VERSION ""

NS_ :

BS_:

BU_: JETSON VCU ACU RES DYN_F DYN_R FSG_DATA_LOGGER AK10_9 Acquisition_Board1 Acquisition_Board2 Acquisition_Board3 Acquisition_Board4 Acquisition_Board7

BO_ 3221225472 VECTOR__INDEPENDENT_SIG_MSG: 0 Vector__XXX
 SG_ WHEEL_SPD : 0|16@1- (0.1,0) [0|0] "ms"  JETSON
 SG_ WHEEL_SPD : 0|16@1- (0.1,0) [0|0] "ms"  JETSON

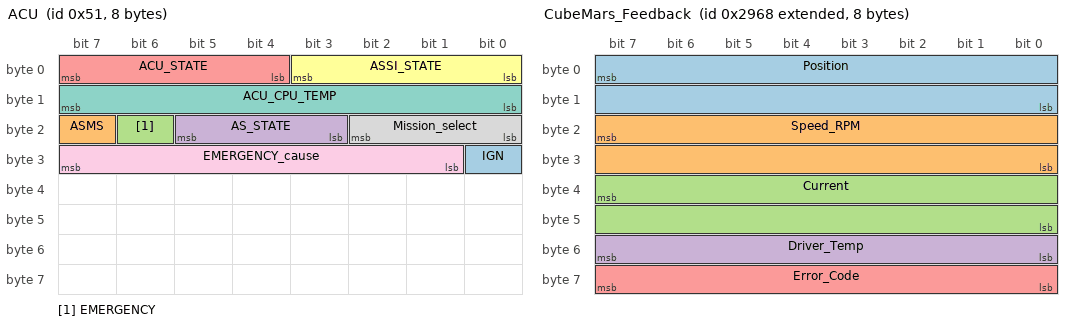
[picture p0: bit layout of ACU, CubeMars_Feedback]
BO_ 81 ACU: 8 ACU
 SG_ IGN : 24|1@1+ (1,0) [0|1] ""  JETSON
 SG_ ASMS : 23|1@1+ (1,0) [0|1] ""  JETSON
 SG_ EMERGENCY : 22|1@1+ (1,0) [0|1] ""  JETSON
 SG_ AS_STATE : 19|3@1+ (1,0) [0|0] ""  JETSON
 SG_ ACU_STATE : 4|4@1+ (1,0) [0|0] ""  JETSON
 SG_ ASSI_STATE : 0|4@1+ (1,0) [0|0] ""  JETSON
 SG_ ACU_CPU_TEMP : 8|8@1+ (1,0) [0|255] "ºc"  JETSON
 SG_ Mission_select : 16|3@1+ (1,0) [0|0] ""  JETSON
 SG_ EMERGENCY_cause : 25|7@1+ (1,0) [0|0] ""  JETSON

BO_ 2147494248 CubeMars_Feedback: 8 AK10_9
 SG_ Position : 7|16@0- (0.1,0) [-3200|3200] "deg"  JETSON
 SG_ Speed_RPM : 23|16@0- (0.0529100529,0) [-1693.121693|1693.121693] "RPM"  JETSON
 SG_ Current : 39|16@0- (0.01,0) [-60|60] "A"  JETSON
 SG_ Driver_Temp : 55|8@0- (1,0) [-20|127] "degC"  JETSON
 SG_ Error_Code : 63|8@0+ (1,0) [0|7] ""  JETSON

BO_ 2147484776 CubeMars_position_loop: 4 JETSON
 SG_ POSITION : 7|32@0- (0.0001,0) [-36000|36000] "deg"  AK10_9

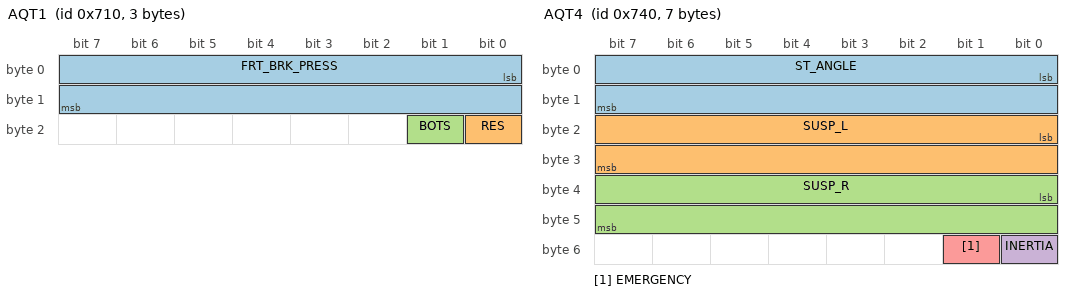
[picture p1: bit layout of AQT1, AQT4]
BO_ 1808 AQT1: 3 Acquisition_Board1
 SG_ FRT_BRK_PRESS : 0|16@1+ (0.1,0) [0|0] "bar"  ACU
 SG_ RES : 16|1@1+ (1,0) [0|0] ""  JETSON
 SG_ BOTS : 17|1@1+ (1,0) [0|0] ""  JETSON

BO_ 1856 AQT4: 7 Acquisition_Board4
 SG_ ST_ANGLE : 0|16@1- (0.1,0) [0|0] "º"  JETSON
 SG_ SUSP_L : 16|16@1- (0.1,0) [0|0] "mm" Vector__XXX
 SG_ SUSP_R : 32|16@1- (0.1,0) [0|0] "mm" Vector__XXX
 SG_ INERTIA : 48|1@1+ (1,0) [0|0] "" Vector__XXX
 SG_ EMERGENCY : 49|1@1+ (1,0) [0|0] "" Vector__XXX

BO_ 1904 AQT7: 2 Acquisition_Board7
 SG_ REAR_BRK_PRESS : 0|16@1+ (0.1,0) [0|0] "bar"  ACU

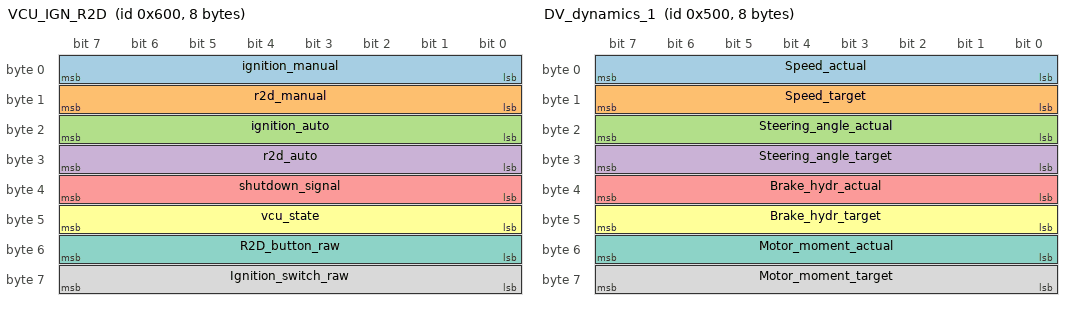
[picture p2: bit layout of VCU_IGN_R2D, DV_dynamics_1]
BO_ 1536 VCU_IGN_R2D: 8 VCU
 SG_ ignition_manual : 0|8@1+ (1,0) [0|0] ""  ACU
 SG_ r2d_manual : 8|8@1+ (1,0) [0|0] ""  ACU
 SG_ ignition_auto : 16|8@1+ (1,0) [0|0] ""  ACU
 SG_ r2d_auto : 24|8@1+ (1,0) [0|0] ""  ACU
 SG_ shutdown_signal : 32|8@1+ (1,0) [0|0] ""  ACU
 SG_ vcu_state : 40|8@1+ (1,0) [0|0] ""  ACU
 SG_ R2D_button_raw : 48|8@1+ (1,0) [0|0] ""  ACU
 SG_ Ignition_switch_raw : 56|8@1+ (1,0) [0|0] ""  ACU

BO_ 1280 DV_dynamics_1: 8 JETSON
 SG_ Speed_actual : 0|8@1+ (1,0) [0|255] "km/h"  FSG_DATA_LOGGER
 SG_ Speed_target : 8|8@1+ (1,0) [0|255] "km/h"  FSG_DATA_LOGGER
 SG_ Steering_angle_actual : 16|8@1- (0.5,0) [-64|63.5] "rad"  FSG_DATA_LOGGER
 SG_ Steering_angle_target : 24|8@1- (0.5,0) [-64|63.5] "rad"  FSG_DATA_LOGGER
 SG_ Brake_hydr_actual : 32|8@1+ (1,0) [0|100] "%"  FSG_DATA_LOGGER
 SG_ Brake_hydr_target : 40|8@1+ (1,0) [0|100] "%"  FSG_DATA_LOGGER
 SG_ Motor_moment_actual : 48|8@1- (1,0) [-128|127] "%"  FSG_DATA_LOGGER
 SG_ Motor_moment_target : 56|8@1- (1,0) [-128|127] "%"  FSG_DATA_LOGGER

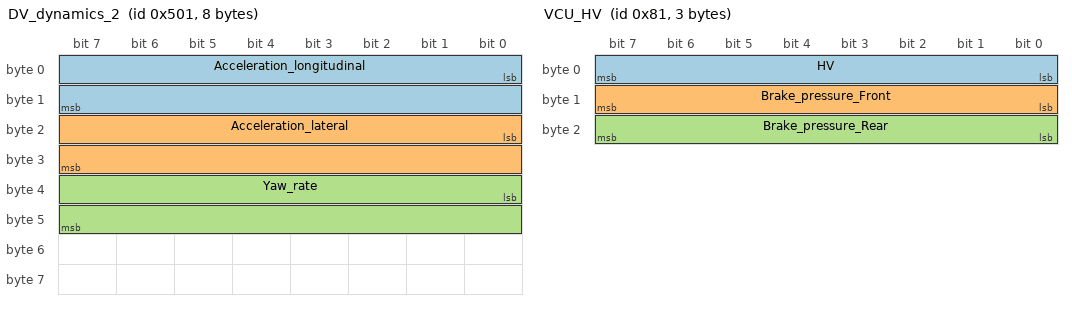
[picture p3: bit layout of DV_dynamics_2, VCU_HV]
BO_ 1281 DV_dynamics_2: 8 JETSON
 SG_ Acceleration_longitudinal : 0|16@1- (0.001953125,0) [0|0] "m/s2"  FSG_DATA_LOGGER
 SG_ Acceleration_lateral : 16|16@1- (0.001953125,0) [0|0] "m/s2"  FSG_DATA_LOGGER
 SG_ Yaw_rate : 32|16@1- (0.0078125,0) [0|0] "m/s2"  FSG_DATA_LOGGER

BO_ 129 VCU_HV: 3 VCU
 SG_ HV : 0|8@1+ (1,0) [0|0] ""  ACU
 SG_ Brake_pressure_Front : 8|8@1+ (1,0) [0|0] ""  ACU
 SG_ Brake_pressure_Rear : 16|8@1+ (1,0) [0|0] ""  ACU

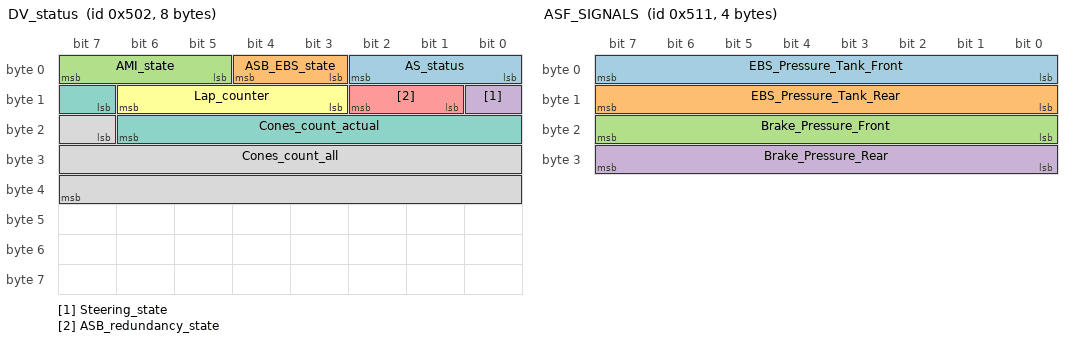
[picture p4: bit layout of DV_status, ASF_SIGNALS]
BO_ 1282 DV_status: 8 ACU
 SG_ AS_status : 0|3@1+ (1,0) [0|7] ""  FSG_DATA_LOGGER
 SG_ ASB_EBS_state : 3|2@1+ (1,0) [0|3] ""  FSG_DATA_LOGGER
 SG_ AMI_state : 5|3@1+ (1,0) [0|7] ""  FSG_DATA_LOGGER
 SG_ Steering_state : 8|1@1+ (1,0) [0|1] ""  FSG_DATA_LOGGER
 SG_ ASB_redundancy_state : 9|2@1+ (1,0) [0|3] ""  FSG_DATA_LOGGER
 SG_ Lap_counter : 11|4@1+ (1,0) [0|15] ""  FSG_DATA_LOGGER
 SG_ Cones_count_actual : 15|8@1+ (1,0) [0|255] ""  FSG_DATA_LOGGER
 SG_ Cones_count_all : 23|17@1+ (1,0) [0|131071] ""  FSG_DATA_LOGGER

BO_ 1297 ASF_SIGNALS: 4 ACU
 SG_ EBS_Pressure_Tank_Front : 0|8@1+ (0.1,0) [0|0] "bar"  FSG_DATA_LOGGER
 SG_ EBS_Pressure_Tank_Rear : 8|8@1+ (0.1,0) [0|0] "bar"  FSG_DATA_LOGGER
 SG_ Brake_Pressure_Front : 16|8@1+ (0.1,0) [0|0] "bar"  FSG_DATA_LOGGER
 SG_ Brake_Pressure_Rear : 24|8@1+ (0.1,0) [0|0] "bar"  FSG_DATA_LOGGER

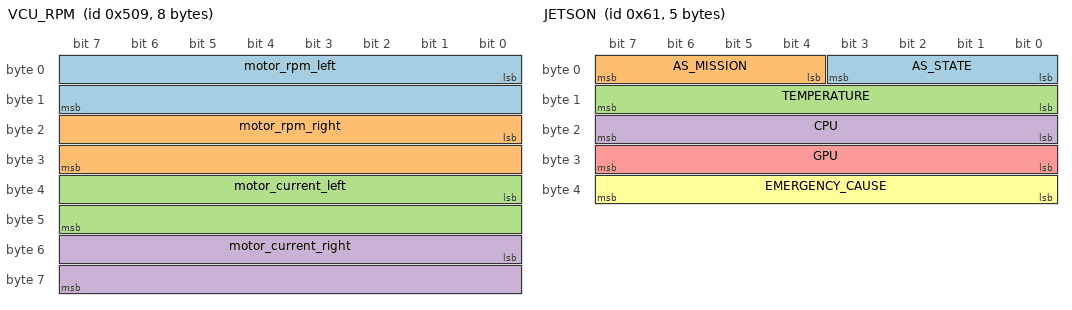
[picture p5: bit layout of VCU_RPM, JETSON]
BO_ 1289 VCU_RPM: 8 VCU
 SG_ motor_rpm_left : 0|16@1+ (1,0) [0|6000] "RPM"  JETSON
 SG_ motor_rpm_right : 16|16@1+ (1,0) [0|0] "RPM" Vector__XXX
 SG_ motor_current_left : 32|16@1- (1,0) [0|0] "A" Vector__XXX
 SG_ motor_current_right : 48|16@1- (1,0) [0|0] "A" Vector__XXX

BO_ 1178 VCU_TORQUE_TARGET: 2 JETSON
 SG_ torque_target : 0|16@1- (1,0) [-100|100] "RPM"  VCU

BO_ 1177 VCU_RPM_TARGET: 2 JETSON
 SG_ rpm_target : 0|16@1- (1,0) [0|6000] "RPM"  VCU

BO_ 97 JETSON: 5 JETSON
 SG_ AS_STATE : 0|4@1+ (1,0) [0|5] ""  ACU
 SG_ AS_MISSION : 4|4@1+ (1,0) [0|7] ""  ACU
 SG_ TEMPERATURE : 8|8@1+ (1,0) [0|100] ""  ACU
 SG_ CPU : 16|8@1+ (1,0) [0|100] ""  ACU
 SG_ GPU : 24|8@1+ (1,0) [0|100] ""  ACU
 SG_ EMERGENCY_CAUSE : 32|8@1+ (1,0) [0|0] ""  ACU

BO_ 401 RES: 8 RES
 SG_ SIGNAL : 0|8@1+ (1,0) [0|0] "" Vector__XXX

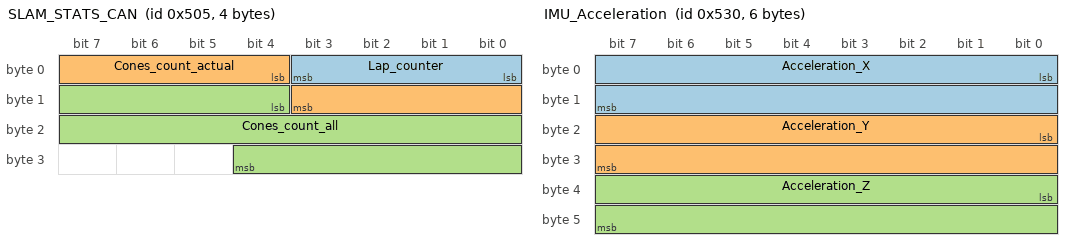
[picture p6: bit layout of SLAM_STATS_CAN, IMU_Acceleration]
BO_ 1285 SLAM_STATS_CAN: 4 JETSON
 SG_ Lap_counter : 0|4@1+ (1,0) [0|0] ""  ACU
 SG_ Cones_count_actual : 4|8@1+ (1,0) [0|0] ""  ACU
 SG_ Cones_count_all : 12|17@1+ (1,0) [0|0] ""  ACU

BO_ 1328 IMU_Acceleration: 6 JETSON
 SG_ Acceleration_X : 0|16@1- (0.01,0) [-327.68|327.67] "m/s^2" Vector__XXX
 SG_ Acceleration_Y : 16|16@1- (0.01,0) [-327.68|327.67] "m/s^2" Vector__XXX
 SG_ Acceleration_Z : 32|16@1- (0.01,0) [-327.68|327.67] "m/s^2" Vector__XXX

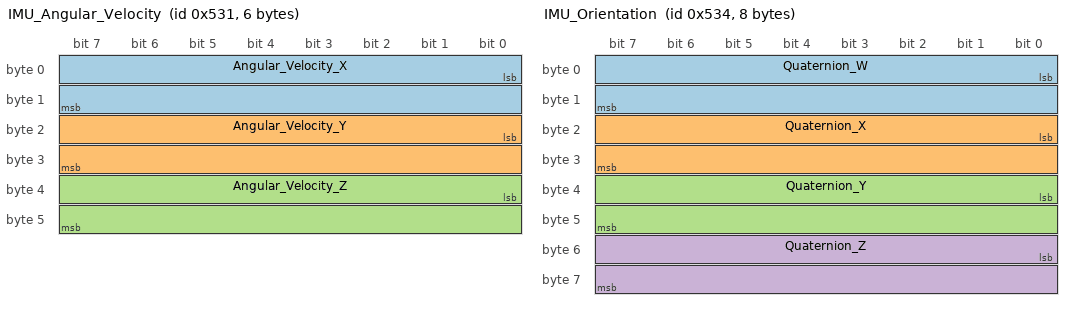
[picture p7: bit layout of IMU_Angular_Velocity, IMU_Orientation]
BO_ 1329 IMU_Angular_Velocity: 6 JETSON
 SG_ Angular_Velocity_X : 0|16@1- (0.001,0) [-32.768|32.767] "rad/s" Vector__XXX
 SG_ Angular_Velocity_Y : 16|16@1- (0.001,0) [-32.768|32.767] "rad/s" Vector__XXX
 SG_ Angular_Velocity_Z : 32|16@1- (0.001,0) [-32.768|32.767] "rad/s" Vector__XXX

BO_ 1330 IMU_GNSS_Position: 8 JETSON
 SG_ Latitude : 0|32@1- (1E-007,0) [-90|90] "deg" Vector__XXX
 SG_ Longitude : 32|32@1- (1E-007,0) [-180|180] "deg" Vector__XXX

BO_ 1331 IMU_GNSS_Altitude: 4 JETSON
 SG_ Altitude : 0|32@1- (0.001,0) [-1000|10000] "m" Vector__XXX

BO_ 1332 IMU_Orientation: 8 JETSON
 SG_ Quaternion_W : 0|16@1- (0.0001,0) [-1|1] "" Vector__XXX
 SG_ Quaternion_X : 16|16@1- (0.0001,0) [-1|1] "" Vector__XXX
 SG_ Quaternion_Y : 32|16@1- (0.0001,0) [-1|1] "" Vector__XXX
 SG_ Quaternion_Z : 48|16@1- (0.0001,0) [-1|1] "" Vector__XXX

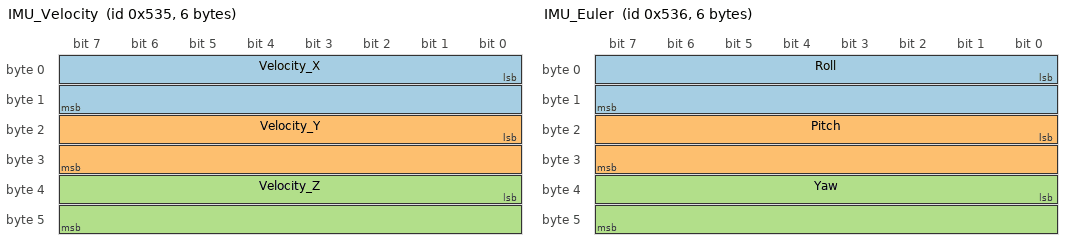
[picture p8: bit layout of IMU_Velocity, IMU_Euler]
BO_ 1333 IMU_Velocity: 6 JETSON
 SG_ Velocity_X : 0|16@1- (0.01,0) [-327.68|327.67] "m/s" Vector__XXX
 SG_ Velocity_Y : 16|16@1- (0.01,0) [-327.68|327.67] "m/s" Vector__XXX
 SG_ Velocity_Z : 32|16@1- (0.01,0) [-327.68|327.67] "m/s" Vector__XXX

BO_ 1334 IMU_Euler: 6 JETSON
 SG_ Roll : 0|16@1- (0.01,0) [-180|180] "deg" Vector__XXX
 SG_ Pitch : 16|16@1- (0.01,0) [-90|90] "deg" Vector__XXX
 SG_ Yaw : 32|16@1- (0.01,0) [-180|180] "deg" Vector__XXX

BO_ 1335 IMU_Status: 4 JETSON
 SG_ Self_Test : 0|1@1+ (1,0) [0|1] "" Vector__XXX
 SG_ Filter_Valid : 1|1@1+ (1,0) [0|1] "" Vector__XXX
 SG_ GNSS_Fix : 2|1@1+ (1,0) [0|1] "" Vector__XXX
 SG_ No_Rotation_Update_Status : 3|2@1+ (1,0) [0|3] "" Vector__XXX
 SG_ Representative_Motion : 5|1@1+ (1,0) [0|1] "" Vector__XXX
 SG_ Clock_Bias_Estimation : 6|1@1+ (1,0) [0|1] "" Vector__XXX
 SG_ Clip_Acc_X : 8|1@1+ (1,0) [0|1] "" Vector__XXX
 SG_ Clip_Acc_Y : 9|1@1+ (1,0) [0|1] "" Vector__XXX
 SG_ Clip_Acc_Z : 10|1@1+ (1,0) [0|1] "" Vector__XXX
 SG_ Clip_Gyr_X : 11|1@1+ (1,0) [0|1] "" Vector__XXX
 SG_ Clip_Gyr_Y : 12|1@1+ (1,0) [0|1] "" Vector__XXX
 SG_ Clip_Gyr_Z : 13|1@1+ (1,0) [0|1] "" Vector__XXX
 SG_ Clip_Mag_X : 14|1@1+ (1,0) [0|1] "" Vector__XXX
 SG_ Clip_Mag_Y : 15|1@1+ (1,0) [0|1] "" Vector__XXX
 SG_ Clip_Mag_Z : 16|1@1+ (1,0) [0|1] "" Vector__XXX
 SG_ Clipping_Indication : 19|1@1+ (1,0) [0|1] "" Vector__XXX
 SG_ SyncIn_Marker : 21|1@1+ (1,0) [0|1] "" Vector__XXX
 SG_ SyncOut_Marker : 22|1@1+ (1,0) [0|1] "" Vector__XXX
 SG_ Filter_Mode : 23|3@1+ (1,0) [0|7] "" Vector__XXX
 SG_ GNSS_Time_Pulse : 26|1@1+ (1,0) [0|1] "" Vector__XXX
 SG_ RTK_Status : 27|2@1+ (1,0) [0|3] "" Vector__XXX

BO_ 1336 IMU_Temperature: 2 JETSON
 SG_ Temperature : 0|16@1- (0.01,0) [-327.68|327.67] "degC" Vector__XXX

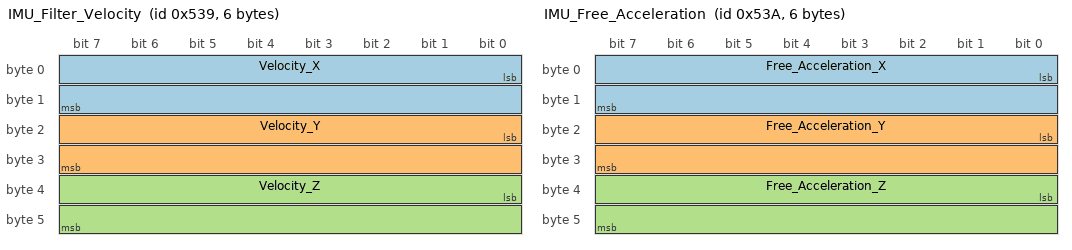
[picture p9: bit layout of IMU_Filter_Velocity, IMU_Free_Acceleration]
BO_ 1337 IMU_Filter_Velocity: 6 JETSON
 SG_ Velocity_X : 0|16@1- (0.01,0) [-327.68|327.67] "m/s" Vector__XXX
 SG_ Velocity_Y : 16|16@1- (0.01,0) [-327.68|327.67] "m/s" Vector__XXX
 SG_ Velocity_Z : 32|16@1- (0.01,0) [-327.68|327.67] "m/s" Vector__XXX

BO_ 1338 IMU_Free_Acceleration: 6 JETSON
 SG_ Free_Acceleration_X : 0|16@1- (0.01,0) [-327.68|327.67] "m/s^2" Vector__XXX
 SG_ Free_Acceleration_Y : 16|16@1- (0.01,0) [-327.68|327.67] "m/s^2" Vector__XXX
 SG_ Free_Acceleration_Z : 32|16@1- (0.01,0) [-327.68|327.67] "m/s^2" Vector__XXX

CM_ BU_ AK10_9 "Atuador direcao";
CM_ SG_ 2147494248 Position " ";
CM_ BO_ 1328 "IMU acceleration in the IMU frame, gravity included. Source: /imu/acceleration (geometry_msgs/Vector3Stamped)";
CM_ BO_ 1329 "IMU angular velocity in the IMU frame. Source: /imu/angular_velocity (geometry_msgs/Vector3Stamped)";
CM_ BO_ 1330 "GNSS position, WGS84. Source: /gnss_pose pose.position.x (latitude) and pose.position.y (longitude)";
CM_ BO_ 1331 "GNSS altitude. Source: /gnss_pose pose.position.z";
CM_ BO_ 1332 "Orientation quaternion. Source: /gnss_pose pose.orientation";
CM_ BO_ 1333 "Velocity in the IMU frame (X forward if the IMU is mounted aligned with the car). Source: /odometry twist.twist.linear (needs pub_odometry: true), or /filter/velocity (ENU) rotated into the IMU frame";
CM_ BO_ 1334 "Orientation as Euler angles, ENU reference (yaw 0 = East, positive counter-clockwise). Source: /filter/euler (geometry_msgs/Vector3Stamped), already in degrees";
CM_ BO_ 1335 "Xsens status word, same bit layout as the device so the raw 32-bit word can be copied in. Source: /status (xsens_mti_ros2_driver/XsStatusWord)";
CM_ BO_ 1336 "IMU temperature. Source: /temperature (sensor_msgs/Temperature)";
CM_ BO_ 1337 "Filter velocity exactly as published by the driver, ENU (X East, Y North, Z Up). Source: /filter/velocity (geometry_msgs/Vector3Stamped)";
CM_ BO_ 1338 "Free acceleration in the local earth frame (ENU), gravity removed. Source: /filter/free_acceleration (geometry_msgs/Vector3Stamped)";
CM_ SG_ 1329 Angular_Velocity_Z "Yaw rate";
CM_ SG_ 1333 Velocity_X "Longitudinal velocity";
CM_ SG_ 1333 Velocity_Y "Lateral velocity";
CM_ SG_ 1335 Filter_Valid "Set when the filter output (orientation, velocity, position) is valid";
CM_ SG_ 1335 GNSS_Fix "Set when the GNSS receiver has a position fix";
CM_ SG_ 1335 Clipping_Indication "Set when any accelerometer, gyroscope or magnetometer axis clipped";
VAL_ 81 IGN 0 "OFF" 1 "ON" ;
VAL_ 81 ASMS 0 "OFF" 1 "ON" ;
VAL_ 81 EMERGENCY 0 "OFF" 1 "ON" ;
VAL_ 81 AS_STATE 1 "OFF" 2 "READY" 3 "DRIVING" 4 "EMERGENCY" 5 "FINISH" ;
VAL_ 81 ACU_STATE 0 "INIT" 1 "MISSION_SELECT" 2 "JETSON_WAITING" 3 "INIT_SEQUENCE" 4 "READY" 5 "DRIVING" 6 "EBS_ERROR" 7 "EMERGENCY" 8 "FINISHED" 9 "MANUAL" ;
VAL_ 81 ASSI_STATE 1 "OFF" 2 "READY" 3 "DRIVING" 4 "EMERGENCY" 5 "FINISH" ;
VAL_ 81 EMERGENCY_cause 0 "None" 1 "SDC_OPEN" 2 "RES" 3 "Pressure_checks" 4 "VCU_timeout" 5 "Jetson_timeout" 6 "ACU_WDT_TRIGGERED" 7 "dir_actuator_timeout" 8 "CAN_Dynamics_Pressure_timeout" ;
VAL_ 2147494248 Error_Code 0 "None" 1 "OVER-VOLTAGE" 2 "UNDER-VOLTAGE" 3 "DRIVER-FAULT" 4 "OVER-CURRENT" 5 "MOSFET-OVER-TEMP" 6 "MOTOR-OVER-TEMP" 7 "GATE-DRIVE-OVER-VOLTAGE" 8 "GATE-DRIVE-UNDER-VOLTAGE" 9 "MCU-UNDER-VOLTAGE" 10 "REBOOTING-FROM-WATCHDOG" 11 "ENCODER-FAULT" 12 "MIN-ENCODER-LIMIT-EXCEEDED" 13 "MAX-ENCODER-LIMIT-EXCEEDED" 14 "FLASH-FAULT" 15 "HIGH-OFFSET-CURRENT-SENSOR1" 16 "HIGH-OFFSET-CURRENT-SENSOR2" ;
VAL_ 1282 AS_status 1 "AS_status_off" 2 "AS_status_ready" 3 "AS_status_driving" 4 "AS_status_emergency" 5 "AS_status_finished" ;
VAL_ 1282 ASB_EBS_state 1 "ASB_EBS_state_deactivated" 2 "ASB_EBS_state_initial_checkup_passed" 3 "ASB_EBS_state_activated" ;
VAL_ 1282 AMI_state 1 "AMI_state_acceleration" 2 "AMI_state_skidpad" 3 "AMI_state_trackdrive" 4 "AMI_state_braketest" 5 "AMI_state_inspection" 6 "AMI_state_autocross" ;
VAL_ 1282 ASB_redundancy_state 1 "ASB_redundancy_state_deactivated" 2 "ASB_redundancy_state_engaged" 3 "ASB_redundancy_state_initial_checkup_passed" ;
VAL_ 97 EMERGENCY_CAUSE 0 "None" 1 "RES" 2 "ACU" 3 "ZED" 4 "Steering_error" 5 "Steering_timeout" 6 "Planner" 7 "SLAM" 8 "P-Puma" 9 "IMU" ;
VAL_ 1335 RTK_Status 0 "No_RTK" 1 "RTK_Floating" 2 "RTK_Fixed" ;
